AUTOSAR XML (schema 4.0)
package /WiperControlSwc  # Wiper Control Software Component
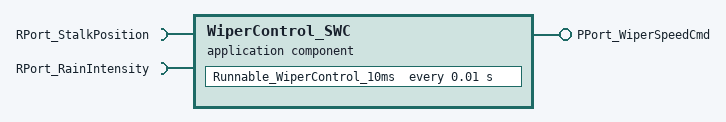
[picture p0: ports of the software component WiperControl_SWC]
  application sw component type WiperControl_SWC  # Automatic Wiper Control Application Software Component
    internal behavior InternalBehavior_WiperControl_SWC
      timing event TE_WiperControl_10ms: start-on-event=Runnable_WiperControl_10ms, period=0.01
      runnable Runnable_WiperControl_10ms
        data-receive-point-by-value-points:
          data receive point by value DRP_StalkPosition: data-destination=StalkPosition
          data receive point by value DRP_RainIntensity: data-destination=RainIntensity
        data send point DSP_WiperSpeedCmd: data-destination=WiperSpeedCmd
    data-type-mappings:
      data StalkPosition: base-type=uint8
      data RainIntensity: base-type=uint8
      data WiperSpeedCmd: base-type=uint8
    require port RPort_StalkPosition
      data receiver point by arguments prototype DRP_StalkPosition: data-element=StalkPosition, data-consistency=EXPLICIT
    require port RPort_RainIntensity
      data receiver point by arguments prototype DRP_RainIntensity: data-element=RainIntensity, data-consistency=EXPLICIT
    provide port PPort_WiperSpeedCmd
      data sender point by arguments prototype DSP_WiperSpeedCmd: data-element=WiperSpeedCmd, data-consistency=EXPLICIT
